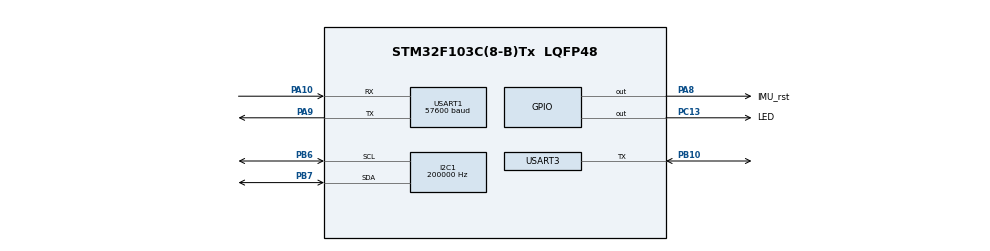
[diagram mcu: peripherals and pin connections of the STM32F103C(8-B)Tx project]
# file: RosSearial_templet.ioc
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Mcu.Family=STM32F1
NVIC.USART3_IRQn=true\:0\:0\:false\:false\:true\:true\:true
PC15-OSC32_OUT.Mode=LSE-External-Oscillator
Dma.USART1_TX.1.Instance=DMA1_Channel4
NVIC.DMA1_Channel5_IRQn=true\:0\:0\:false\:false\:true\:false\:true
PD1-OSC_OUT.Mode=HSE-External-Oscillator
Dma.USART1_RX.0.PeriphDataAlignment=DMA_PDATAALIGN_BYTE
PA10.Mode=Asynchronous
Dma.USART3_TX.3.PeriphDataAlignment=DMA_PDATAALIGN_BYTE
Dma.USART1_TX.1.MemInc=DMA_MINC_ENABLE
PB10.Mode=Half_duplex(single_wire_mode)
Dma.USART3_RX.2.Mode=DMA_CIRCULAR
USART1.BaudRate=57600
Dma.USART3_TX.3.MemInc=DMA_MINC_ENABLE
PC13-TAMPER-RTC.Signal=GPIO_Output
NVIC.TIM1_UP_IRQn=true\:0\:0\:false\:false\:true\:false\:true
PD0-OSC_IN.Signal=RCC_OSC_IN
Dma.USART3_TX.3.MemDataAlignment=DMA_MDATAALIGN_BYTE
PC14-OSC32_IN.Signal=RCC_OSC32_IN
Dma.USART3_TX.3.PeriphInc=DMA_PINC_DISABLE
ProjectManager.StackSize=0x400
PD1-OSC_OUT.Signal=RCC_OSC_OUT
NVIC.DMA1_Channel3_IRQn=true\:0\:0\:false\:false\:true\:false\:true
PA13.Signal=SYS_JTMS-SWDIO
Dma.USART3_RX.2.Priority=DMA_PRIORITY_MEDIUM
PA9.Mode=Asynchronous
Dma.USART3_RX.2.PeriphDataAlignment=DMA_PDATAALIGN_BYTE
PA8.GPIO_Label=IMU_rst
Dma.USART3_RX.2.MemInc=DMA_MINC_ENABLE
USART3.BaudRate=57200
I2C1.ClockSpeed=200000
NVIC.DMA1_Channel2_IRQn=true\:0\:0\:false\:false\:true\:false\:true
ProjectManager.TargetToolchain=STM32CubeIDE
I2C1.I2C_Mode=I2C_Fast
Dma.USART3_RX.2.PeriphInc=DMA_PINC_DISABLE
Dma.USART1_RX.0.Direction=DMA_PERIPH_TO_MEMORY
PA9.Signal=USART1_TX
PB6.Signal=I2C1_SCL
PB6.Mode=I2C
Dma.USART3_RX.2.Direction=DMA_PERIPH_TO_MEMORY
PC15-OSC32_OUT.Signal=RCC_OSC32_OUT
Dma.USART1_RX.0.PeriphInc=DMA_PINC_DISABLE
Dma.USART1_RX.0.Priority=DMA_PRIORITY_HIGH
PB10.Signal=USART3_TX
PD0-OSC_IN.Mode=HSE-External-Oscillator
Dma.USART3_TX.3.Instance=DMA1_Channel2
Dma.USART1_TX.1.MemDataAlignment=DMA_MDATAALIGN_BYTE
board=custom
PC13-TAMPER-RTC.GPIO_Label=LED
RCC.APB2Freq_Value=8000000
Dma.USART3_TX.3.Direction=DMA_MEMORY_TO_PERIPH
PC14-OSC32_IN.Mode=LSE-External-Oscillator
PA14.Mode=Serial_Wire
VP_SYS_VS_tim1.Mode=TIM1
Dma.USART1_RX.0.MemDataAlignment=DMA_MDATAALIGN_BYTE
PB7.Signal=I2C1_SDA
PA8.Signal=GPIO_Output
Dma.USART1_RX.0.MemInc=DMA_MINC_ENABLE
PA13.Mode=Serial_Wire
Mcu.Name=STM32F103C(8-B)Tx
Dma.USART1_TX.1.PeriphDataAlignment=DMA_PDATAALIGN_BYTE
Dma.USART3_TX.3.Mode=DMA_NORMAL
Mcu.Package=LQFP48
NVIC.TimeBase=TIM1_UP_IRQn
USART3.VirtualMode=VM_ASYNC
Dma.USART1_TX.1.Mode=DMA_NORMAL
USART1.VirtualMode=VM_ASYNC
PB7.Mode=I2C
NVIC.TimeBaseIP=TIM1
PA14.Signal=SYS_JTCK-SWCLK
PA10.Signal=USART1_RX
ProjectManager.HeapSize=0x200
Dma.USART1_TX.1.PeriphInc=DMA_PINC_DISABLE
Dma.USART3_RX.2.MemDataAlignment=DMA_MDATAALIGN_BYTE
NVIC.PriorityGroup=NVIC_PRIORITYGROUP_4
Dma.Request2=USART3_RX
Dma.Request1=USART1_TX
Dma.Request3=USART3_TX
Dma.USART1_RX.0.Mode=DMA_CIRCULAR
Dma.USART1_TX.1.Priority=DMA_PRIORITY_HIGH
NVIC.DMA1_Channel4_IRQn=true\:0\:0\:false\:false\:true\:false\:true
Dma.USART3_RX.2.Instance=DMA1_Channel3
NVIC.USART1_IRQn=true\:0\:0\:false\:false\:true\:true\:true
Dma.Request0=USART1_RX
RCC.APB1Freq_Value=8000000
Dma.USART1_RX.0.Instance=DMA1_Channel5
PA8.PinState=GPIO_PIN_SET
Dma.USART3_TX.3.Priority=DMA_PRIORITY_MEDIUM
Dma.USART1_TX.1.Direction=DMA_MEMORY_TO_PERIPH

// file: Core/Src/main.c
/* USER CODE BEGIN Header */
/**
  ******************************************************************************
  * @file           : main.c
  * @brief          : Main program body
  ******************************************************************************
  * @attention
  *
  * <h2><center>&copy; Copyright (c) 2021 STMicroelectronics.
  * All rights reserved.</center></h2>
  *
  * This software component is licensed by ST under BSD 3-Clause license,
  * the "License"; You may not use this file except in compliance with the
  * License. You may obtain a copy of the License at:
  *                        opensource.org/licenses/BSD-3-Clause
  *
  ******************************************************************************
  */
/* USER CODE END Header */
#include "main.h"

/* USER CODE BEGIN Includes */
#include "maincpp.h"
#include "xl430.h"

/* USER CODE END Includes */

I2C_HandleTypeDef hi2c1;

UART_HandleTypeDef huart1;
UART_HandleTypeDef huart3;
DMA_HandleTypeDef hdma_usart1_rx;
DMA_HandleTypeDef hdma_usart1_tx;
DMA_HandleTypeDef hdma_usart3_rx;
DMA_HandleTypeDef hdma_usart3_tx;

/* USER CODE BEGIN PV */

//uint8_t tx_[64] ;
/* USER CODE END PV */

void SystemClock_Config(void);
static void MX_GPIO_Init(void);
static void MX_DMA_Init(void);
static void MX_USART1_UART_Init(void);
static void MX_USART3_UART_Init(void);
static void MX_I2C1_Init(void);

int main(void)
{

  /* MCU Configuration--------------------------------------------------------*/

  /* Reset of all peripherals, Initializes the Flash interface and the Systick. */
  HAL_Init();

  /* Configure the system clock */
  SystemClock_Config();

  /* Initialize all configured peripherals */
  MX_GPIO_Init();
  MX_DMA_Init();
  MX_USART1_UART_Init();
  MX_USART3_UART_Init();
  MX_I2C1_Init();
  /* USER CODE BEGIN 2 */

  xl430_int(&huart3);
  setup();

  /* USER CODE END 2 */

  /* Infinite loop */
  /* USER CODE BEGIN WHILE */
  while (1)
  {
	  setup_dummy();

    /* USER CODE END WHILE */

  }
}

void SystemClock_Config(void)
{
  RCC_OscInitTypeDef RCC_OscInitStruct = {0};
  RCC_ClkInitTypeDef RCC_ClkInitStruct = {0};

  /** Initializes the RCC Oscillators according to the specified parameters
  * in the RCC_OscInitTypeDef structure.
  */
  RCC_OscInitStruct.OscillatorType = RCC_OSCILLATORTYPE_HSI;
  RCC_OscInitStruct.HSIState = RCC_HSI_ON;
  RCC_OscInitStruct.HSICalibrationValue = RCC_HSICALIBRATION_DEFAULT;
  RCC_OscInitStruct.PLL.PLLState = RCC_PLL_NONE;
  if (HAL_RCC_OscConfig(&RCC_OscInitStruct) != HAL_OK)
  {
    Error_Handler();
  }
  /** Initializes the CPU, AHB and APB buses clocks
  */
  RCC_ClkInitStruct.ClockType = RCC_CLOCKTYPE_HCLK|RCC_CLOCKTYPE_SYSCLK
                              |RCC_CLOCKTYPE_PCLK1|RCC_CLOCKTYPE_PCLK2;
  RCC_ClkInitStruct.SYSCLKSource = RCC_SYSCLKSOURCE_HSI;
  RCC_ClkInitStruct.AHBCLKDivider = RCC_SYSCLK_DIV1;
  RCC_ClkInitStruct.APB1CLKDivider = RCC_HCLK_DIV1;
  RCC_ClkInitStruct.APB2CLKDivider = RCC_HCLK_DIV1;

  if (HAL_RCC_ClockConfig(&RCC_ClkInitStruct, FLASH_LATENCY_0) != HAL_OK)
  {
    Error_Handler();
  }
}

static void MX_I2C1_Init(void)
{

  hi2c1.Instance = I2C1;
  hi2c1.Init.ClockSpeed = 200000;
  hi2c1.Init.DutyCycle = I2C_DUTYCYCLE_2;
  hi2c1.Init.OwnAddress1 = 0;
  hi2c1.Init.AddressingMode = I2C_ADDRESSINGMODE_7BIT;
  hi2c1.Init.DualAddressMode = I2C_DUALADDRESS_DISABLE;
  hi2c1.Init.OwnAddress2 = 0;
  hi2c1.Init.GeneralCallMode = I2C_GENERALCALL_DISABLE;
  hi2c1.Init.NoStretchMode = I2C_NOSTRETCH_DISABLE;
  if (HAL_I2C_Init(&hi2c1) != HAL_OK)
  {
    Error_Handler();
  }

}

static void MX_USART1_UART_Init(void)
{

  huart1.Instance = USART1;
  huart1.Init.BaudRate = 57600;
  huart1.Init.WordLength = UART_WORDLENGTH_8B;
  huart1.Init.StopBits = UART_STOPBITS_1;
  huart1.Init.Parity = UART_PARITY_NONE;
  huart1.Init.Mode = UART_MODE_TX_RX;
  huart1.Init.HwFlowCtl = UART_HWCONTROL_NONE;
  huart1.Init.OverSampling = UART_OVERSAMPLING_16;
  if (HAL_UART_Init(&huart1) != HAL_OK)
  {
    Error_Handler();
  }

}

static void MX_USART3_UART_Init(void)
{

  huart3.Instance = USART3;
  huart3.Init.BaudRate = 57200;
  huart3.Init.WordLength = UART_WORDLENGTH_8B;
  huart3.Init.StopBits = UART_STOPBITS_1;
  huart3.Init.Parity = UART_PARITY_NONE;
  huart3.Init.Mode = UART_MODE_TX_RX;
  huart3.Init.HwFlowCtl = UART_HWCONTROL_NONE;
  huart3.Init.OverSampling = UART_OVERSAMPLING_16;
  if (HAL_HalfDuplex_Init(&huart3) != HAL_OK)
  {
    Error_Handler();
  }
  /* USER CODE BEGIN USART3_Init 2 */
  __HAL_UART_ENABLE_IT(&huart3, UART_IT_IDLE);
  __HAL_UART_ENABLE_IT(&huart3, UART_IT_TC);

  /* USER CODE END USART3_Init 2 */

}

static void MX_DMA_Init(void)
{

  /* DMA controller clock enable */
  __HAL_RCC_DMA1_CLK_ENABLE();

  /* DMA interrupt init */
  /* DMA1_Channel2_IRQn interrupt configuration */
  HAL_NVIC_SetPriority(DMA1_Channel2_IRQn, 0, 0);
  HAL_NVIC_EnableIRQ(DMA1_Channel2_IRQn);
  /* DMA1_Channel3_IRQn interrupt configuration */
  HAL_NVIC_SetPriority(DMA1_Channel3_IRQn, 0, 0);
  HAL_NVIC_EnableIRQ(DMA1_Channel3_IRQn);
  /* DMA1_Channel4_IRQn interrupt configuration */
  HAL_NVIC_SetPriority(DMA1_Channel4_IRQn, 0, 0);
  HAL_NVIC_EnableIRQ(DMA1_Channel4_IRQn);
  /* DMA1_Channel5_IRQn interrupt configuration */
  HAL_NVIC_SetPriority(DMA1_Channel5_IRQn, 0, 0);
  HAL_NVIC_EnableIRQ(DMA1_Channel5_IRQn);

}

static void MX_GPIO_Init(void)
{
  GPIO_InitTypeDef GPIO_InitStruct = {0};

  /* GPIO Ports Clock Enable */
  __HAL_RCC_GPIOC_CLK_ENABLE();
  __HAL_RCC_GPIOD_CLK_ENABLE();
  __HAL_RCC_GPIOB_CLK_ENABLE();
  __HAL_RCC_GPIOA_CLK_ENABLE();

  /*Configure GPIO pin Output Level */
  HAL_GPIO_WritePin(LED_GPIO_Port, LED_Pin, GPIO_PIN_RESET);

  /*Configure GPIO pin Output Level */
  HAL_GPIO_WritePin(IMU_rst_GPIO_Port, IMU_rst_Pin, GPIO_PIN_SET);

  /*Configure GPIO pin : LED_Pin */
  GPIO_InitStruct.Pin = LED_Pin;
  GPIO_InitStruct.Mode = GPIO_MODE_OUTPUT_PP;
  GPIO_InitStruct.Pull = GPIO_NOPULL;
  GPIO_InitStruct.Speed = GPIO_SPEED_FREQ_LOW;
  HAL_GPIO_Init(LED_GPIO_Port, &GPIO_InitStruct);

  /*Configure GPIO pin : IMU_rst_Pin */
  GPIO_InitStruct.Pin = IMU_rst_Pin;
  GPIO_InitStruct.Mode = GPIO_MODE_OUTPUT_PP;
  GPIO_InitStruct.Pull = GPIO_NOPULL;
  GPIO_InitStruct.Speed = GPIO_SPEED_FREQ_LOW;
  HAL_GPIO_Init(IMU_rst_GPIO_Port, &GPIO_InitStruct);

}

 /**
  * @brief  Period elapsed callback in non blocking mode
  * @note   This function is called  when TIM1 interrupt took place, inside
  * HAL_TIM_IRQHandler(). It makes a direct call to HAL_IncTick() to increment
  * a global variable "uwTick" used as application time base.
  * @param  htim : TIM handle
  * @retval None
  */
void HAL_TIM_PeriodElapsedCallback(TIM_HandleTypeDef *htim)
{
  if (htim->Instance == TIM1) {
    HAL_IncTick();
  }
}

void Error_Handler(void)
{
  __disable_irq();
  while (1)
  {
  }
}

/************************ (C) COPYRIGHT STMicroelectronics *****END OF FILE****/
